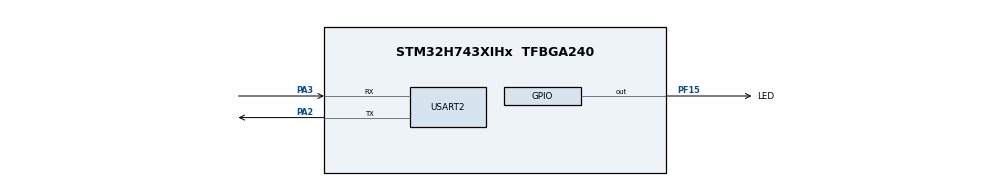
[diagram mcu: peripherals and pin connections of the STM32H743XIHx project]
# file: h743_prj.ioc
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CORTEX_M7.default_mode_Activation=1
FREERTOS.Queues01=uartQueue,128,1,1,Dynamic,NULL,NULL
FREERTOS.Tasks01=defaultTask,0,128,StartDefaultTask,Default,NULL,Dynamic,NULL,NULL
FREERTOS.configUSE_NEWLIB_REENTRANT=0
FREERTOS.configUSE_TICKLESS_IDLE=1
FREERTOS.configUSE_TIMERS=1
IWDG1.Prescaler=IWDG_PRESCALER_32
Mcu.Family=STM32H7
Mcu.Name=STM32H743XIHx
Mcu.Package=TFBGA240
NVIC.LPTIM1_IRQn=true\:5\:0\:false\:false\:true\:true\:true\:true\:true
NVIC.PriorityGroup=NVIC_PRIORITYGROUP_4
NVIC.TIM6_DAC_IRQn=true\:5\:0\:false\:false\:true\:true\:true\:true\:true
NVIC.TIM7_IRQn=true\:15\:0\:false\:false\:true\:false\:false\:true\:true
NVIC.TimeBase=TIM7_IRQn
NVIC.TimeBaseIP=TIM7
NVIC.USART2_IRQn=true\:5\:0\:false\:false\:true\:true\:true\:true\:true
PA13\ (JTMS/SWDIO).Mode=Serial_Wire
PA13\ (JTMS/SWDIO).Signal=DEBUG_JTMS-SWDIO
PA14\ (JTCK/SWCLK).Mode=Serial_Wire
PA14\ (JTCK/SWCLK).Signal=DEBUG_JTCK-SWCLK
PA2.Mode=Asynchronous
PA2.Signal=USART2_TX
PA3.Mode=Asynchronous
PA3.Signal=USART2_RX
PF15.GPIO_Label=LED
PF15.Signal=GPIO_Output
PH0-OSC_IN\ (PH0).Mode=HSE-External-Oscillator
PH0-OSC_IN\ (PH0).Signal=RCC_OSC_IN
PH1-OSC_OUT\ (PH1).Mode=HSE-External-Oscillator
PH1-OSC_OUT\ (PH1).Signal=RCC_OSC_OUT
ProjectManager.HeapSize=0x200
ProjectManager.StackSize=0x400
ProjectManager.TargetToolchain=MDK-ARM V5.32
RCC.ADCFreq_Value=50390625
RCC.APB1Freq_Value=120000000
RCC.APB2Freq_Value=120000000
RCC.APB3Freq_Value=120000000
RCC.APB4Freq_Value=120000000
RCC.CortexFreq_Value=480000000
RCC.D1PPRE=RCC_APB3_DIV2
RCC.D2PPRE1=RCC_APB1_DIV2
RCC.D2PPRE2=RCC_APB2_DIV2
RCC.D3PPRE=RCC_APB4_DIV2
RCC.DIVM1=5
RCC.DIVN1=192
RCC.HCLKFreq_Value=240000000
RCC.HPRE=RCC_HCLK_DIV2
RCC.LPTIM1CLockSelection=RCC_LPTIM1CLKSOURCE_LSI
RCC.PLLSourceVirtual=RCC_PLLSOURCE_HSE
RCC.SYSCLKFreq_VALUE=480000000
RCC.SYSCLKSource=RCC_SYSCLKSOURCE_PLLCLK
RCC.USBFreq_Value=480000000
TIM6.Period=99
TIM6.Prescaler=239
USART2.VirtualMode-Asynchronous=VM_ASYNC
VP_FREERTOS_VS_CMSIS_V1.Mode=CMSIS_V1
VP_IWDG1_VS_IWDG.Mode=IWDG_Activate
VP_LPTIM1_VS_LPTIM_counterModeInternalClock.Mode=Counts__internal_clock_event_00
VP_MEMORYMAP_VS_MEMORYMAP.Mode=CurAppReg
VP_SYS_VS_tim7.Mode=TIM7
VP_TIM6_VS_ClockSourceINT.Mode=Enable_Timer
board=custom

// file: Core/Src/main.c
/* USER CODE BEGIN Header */
/**
  ******************************************************************************
  * @file           : main.c
  * @brief          : Main program body
  ******************************************************************************
  * @attention
  *
  * Copyright (c) 2026 STMicroelectronics.
  * All rights reserved.
  *
  * This software is licensed under terms that can be found in the LICENSE file
  * in the root directory of this software component.
  * If no LICENSE file comes with this software, it is provided AS-IS.
  *
  ******************************************************************************
  */
/* USER CODE END Header */
#include "main.h"
#include "cmsis_os.h"
#include "iwdg.h"
#include "lptim.h"
#include "tim.h"
#include "usart.h"
#include "gpio.h"

/* USER CODE BEGIN Includes */
#include "FreeRTOS.h"
#include "task.h"
#include "queue.h"
#include "string.h"
#include "stdio.h"
#include "timers.h"
#include "test_api.h"
#include "cm_backtrace.h"
#include "event_groups.h"
/* USER CODE END Includes */

/* USER CODE BEGIN PTD */
// 定义事件位
#define BIT_TASK_1_DONE      (1 << 0)    //
#define BIT_TASK_2_DONE      (1 << 1)    //
#define BIT_TASK_3_DONE      (1 << 2)    //

#define BIT_TASK_ALL_DONE    (BIT_TASK_1_DONE | BIT_TASK_2_DONE | BIT_TASK_3_DONE)
/* USER CODE END PTD */

/* USER CODE BEGIN PD */
// 事件标志组句柄
EventGroupHandle_t xSensorEventGroup;
// 串口接收缓存
uint8_t rx_byte;
/* USER CODE END PD */

void SystemClock_Config(void);
static void MPU_Config(void);
void MX_FREERTOS_Init(void);
/* USER CODE BEGIN PFP */
void Task_1(void *pvParameters);
void Task_2(void *pvParameters);
void Task_3(void *pvParameters);
void Task_Monitor(void *pvParameters);

/* USER CODE END PFP */

int main(void)
{

  /* MPU Configuration--------------------------------------------------------*/
  MPU_Config();

  /* MCU Configuration--------------------------------------------------------*/

  /* Reset of all peripherals, Initializes the Flash interface and the Systick. */
  HAL_Init();

  /* Configure the system clock */
  SystemClock_Config();

  /* USER CODE BEGIN SysInit */
  HAL_EnableDBGStopMode();
  /* USER CODE END SysInit */

  /* Initialize all configured peripherals */
  MX_GPIO_Init();
  MX_TIM6_Init();
  MX_USART2_UART_Init();
  MX_LPTIM1_Init();
  MX_IWDG1_Init();
  /* USER CODE BEGIN 2 */
  // 初始化cmbacktrace
  cm_backtrace_init("h743_prj", "v1.0", "v1011");
  printf("System init done\r\n");

  HAL_IWDG_Refresh(&hiwdg1);

  xSensorEventGroup = xEventGroupCreate();
  if (xSensorEventGroup != NULL)
  {
    xTaskCreate(Task_1, "Task_1", 256, NULL, 1, NULL);
    xTaskCreate(Task_2, "Task_2", 256, NULL, 1, NULL);
    xTaskCreate(Task_3, "Task_3", 256, NULL, 1, NULL);
    xTaskCreate(Task_Monitor, "Monitor", 512, NULL, 2, NULL);

    // 启动tim6中断
    // HAL_TIM_Base_Start_IT(&htim6);
    // 启动串口接收
    // HAL_UART_Receive_IT(&huart2, &rx_byte, 1);

  }

  /* USER CODE END 2 */

  /* Call init function for freertos objects (in cmsis_os2.c) */
  MX_FREERTOS_Init();

  /* Start scheduler */
  osKernelStart();

  /* We should never get here as control is now taken by the scheduler */

  /* Infinite loop */
  /* USER CODE BEGIN WHILE */
  // uint8_t msg[] = "hello word\r\n";
  while (1)
  {
    /* USER CODE END WHILE */

  }
}

void SystemClock_Config(void)
{
  RCC_OscInitTypeDef RCC_OscInitStruct = {0};
  RCC_ClkInitTypeDef RCC_ClkInitStruct = {0};

  /** Supply configuration update enable
  */
  HAL_PWREx_ConfigSupply(PWR_LDO_SUPPLY);

  /** Configure the main internal regulator output voltage
  */
  __HAL_PWR_VOLTAGESCALING_CONFIG(PWR_REGULATOR_VOLTAGE_SCALE0);

  while(!__HAL_PWR_GET_FLAG(PWR_FLAG_VOSRDY)) {}

  /** Initializes the RCC Oscillators according to the specified parameters
  * in the RCC_OscInitTypeDef structure.
  */
  RCC_OscInitStruct.OscillatorType = RCC_OSCILLATORTYPE_LSI|RCC_OSCILLATORTYPE_HSE;
  RCC_OscInitStruct.HSEState = RCC_HSE_ON;
  RCC_OscInitStruct.LSIState = RCC_LSI_ON;
  RCC_OscInitStruct.PLL.PLLState = RCC_PLL_ON;
  RCC_OscInitStruct.PLL.PLLSource = RCC_PLLSOURCE_HSE;
  RCC_OscInitStruct.PLL.PLLM = 5;
  RCC_OscInitStruct.PLL.PLLN = 192;
  RCC_OscInitStruct.PLL.PLLP = 2;
  RCC_OscInitStruct.PLL.PLLQ = 2;
  RCC_OscInitStruct.PLL.PLLR = 2;
  RCC_OscInitStruct.PLL.PLLRGE = RCC_PLL1VCIRANGE_2;
  RCC_OscInitStruct.PLL.PLLVCOSEL = RCC_PLL1VCOWIDE;
  RCC_OscInitStruct.PLL.PLLFRACN = 0;
  if (HAL_RCC_OscConfig(&RCC_OscInitStruct) != HAL_OK)
  {
    Error_Handler();
  }

  /** Initializes the CPU, AHB and APB buses clocks
  */
  RCC_ClkInitStruct.ClockType = RCC_CLOCKTYPE_HCLK|RCC_CLOCKTYPE_SYSCLK
                              |RCC_CLOCKTYPE_PCLK1|RCC_CLOCKTYPE_PCLK2
                              |RCC_CLOCKTYPE_D3PCLK1|RCC_CLOCKTYPE_D1PCLK1;
  RCC_ClkInitStruct.SYSCLKSource = RCC_SYSCLKSOURCE_PLLCLK;
  RCC_ClkInitStruct.SYSCLKDivider = RCC_SYSCLK_DIV1;
  RCC_ClkInitStruct.AHBCLKDivider = RCC_HCLK_DIV2;
  RCC_ClkInitStruct.APB3CLKDivider = RCC_APB3_DIV2;
  RCC_ClkInitStruct.APB1CLKDivider = RCC_APB1_DIV2;
  RCC_ClkInitStruct.APB2CLKDivider = RCC_APB2_DIV2;
  RCC_ClkInitStruct.APB4CLKDivider = RCC_APB4_DIV2;

  if (HAL_RCC_ClockConfig(&RCC_ClkInitStruct, FLASH_LATENCY_4) != HAL_OK)
  {
    Error_Handler();
  }
}

/* USER CODE BEGIN 4 */

/* printf重定向 */
#ifdef GNU
int __io_putchar(int ch)
{
  HAL_UART_Transmit(&huart2, (uint8_t*)&ch, 1, 100);
  return ch;
}
#else
int fputc(int ch, FILE *f)
{
  while ((USART2->ISR & USART_ISR_TXE_TXFNF) == 0);
  USART2->TDR = (uint8_t)ch;
  return ch;
}
#endif

// 串口中断回调函数
void HAL_UART_RxCpltCallback(UART_HandleTypeDef *huart)
{
  if (huart->Instance == USART2)
  {

  }
}

/*  */
void Task_1(void *pvParameters)
{

  for (;;)
  {
    vTaskDelay(1000);
    xEventGroupSetBits(xSensorEventGroup, BIT_TASK_1_DONE);
  }
}

/*  */
void Task_2(void *pvParameters)
{
  for(;;)
  {
    vTaskDelay(1500);
    xEventGroupSetBits(xSensorEventGroup, BIT_TASK_2_DONE);
  }
}

/* 制造卡死任务 */
void Task_3(void *pvParameters)
{

  for (;;)
  {
    if ((USART2->ISR & USART_ISR_RXNE_RXFNE) != 0)
    {
      char cmd = USART2->RDR;
      if (cmd == 'K')
      {
        printf("[ERROR] Task 3 Crashed\r\n");
        while (1);
      }
    }

    vTaskDelay(pdMS_TO_TICKS(500));
    xEventGroupSetBits(xSensorEventGroup, BIT_TASK_3_DONE);
  }
}

/* 监控任务 */
void Task_Monitor(void *pvParameters)
{
  EventBits_t uBits = 0;

  for (;;)
  {
    uBits = xEventGroupWaitBits(
      xSensorEventGroup,
      BIT_TASK_ALL_DONE,
      pdTRUE,
      pdTRUE,
      pdMS_TO_TICKS(3000));

    if ((uBits & BIT_TASK_ALL_DONE) == BIT_TASK_ALL_DONE)
    {
      HAL_IWDG_Refresh(&hiwdg1);
      printf("wdg ok\r\n");
    }
    else
    {
      printf("wdg overtime\r\n");
    }
  }
}

/* USER CODE END 4 */

 /* MPU Configuration */

void MPU_Config(void)
{
  MPU_Region_InitTypeDef MPU_InitStruct = {0};

  /* Disables the MPU */
  HAL_MPU_Disable();

  /** Initializes and configures the Region and the memory to be protected
  */
  MPU_InitStruct.Enable = MPU_REGION_ENABLE;
  MPU_InitStruct.Number = MPU_REGION_NUMBER0;
  MPU_InitStruct.BaseAddress = 0x0;
  MPU_InitStruct.Size = MPU_REGION_SIZE_4GB;
  MPU_InitStruct.SubRegionDisable = 0x87;
  MPU_InitStruct.TypeExtField = MPU_TEX_LEVEL0;
  MPU_InitStruct.AccessPermission = MPU_REGION_NO_ACCESS;
  MPU_InitStruct.DisableExec = MPU_INSTRUCTION_ACCESS_DISABLE;
  MPU_InitStruct.IsShareable = MPU_ACCESS_SHAREABLE;
  MPU_InitStruct.IsCacheable = MPU_ACCESS_NOT_CACHEABLE;
  MPU_InitStruct.IsBufferable = MPU_ACCESS_NOT_BUFFERABLE;

  HAL_MPU_ConfigRegion(&MPU_InitStruct);
  /* Enables the MPU */
  HAL_MPU_Enable(MPU_PRIVILEGED_DEFAULT);

}

void HAL_TIM_PeriodElapsedCallback(TIM_HandleTypeDef *htim)
{
  /* USER CODE BEGIN Callback 0 */
  if (htim->Instance == TIM6)
  {

  }
  /* USER CODE END Callback 0 */
  if (htim->Instance == TIM7)
  {
    HAL_IncTick();
  }
}

void Error_Handler(void)
{
  __disable_irq();
  while (1)
  {
  }
}

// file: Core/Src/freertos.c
/* USER CODE BEGIN Header */
/**
  ******************************************************************************
  * File Name          : freertos.c
  * Description        : Code for freertos applications
  ******************************************************************************
  * @attention
  *
  * Copyright (c) 2026 STMicroelectronics.
  * All rights reserved.
  *
  * This software is licensed under terms that can be found in the LICENSE file
  * in the root directory of this software component.
  * If no LICENSE file comes with this software, it is provided AS-IS.
  *
  ******************************************************************************
  */
/* USER CODE END Header */

#include "FreeRTOS.h"
#include "task.h"
#include "main.h"
#include "cmsis_os.h"

osThreadId defaultTaskHandle;
osMessageQId uartQueueHandle;

void StartDefaultTask(void const * argument);

void MX_FREERTOS_Init(void); /* (MISRA C 2004 rule 8.1) */

/* GetIdleTaskMemory prototype (linked to static allocation support) */
void vApplicationGetIdleTaskMemory( StaticTask_t **ppxIdleTaskTCBBuffer, StackType_t **ppxIdleTaskStackBuffer, uint32_t *pulIdleTaskStackSize );

/* GetTimerTaskMemory prototype (linked to static allocation support) */
void vApplicationGetTimerTaskMemory( StaticTask_t **ppxTimerTaskTCBBuffer, StackType_t **ppxTimerTaskStackBuffer, uint32_t *pulTimerTaskStackSize );

/* USER CODE BEGIN PREPOSTSLEEP */
__weak void PreSleepProcessing(uint32_t ulExpectedIdleTime)
{
/* place for user code */
}

__weak void PostSleepProcessing(uint32_t ulExpectedIdleTime)
{
/* place for user code */
}
/* USER CODE END PREPOSTSLEEP */

/* USER CODE BEGIN GET_IDLE_TASK_MEMORY */
static StaticTask_t xIdleTaskTCBBuffer;
static StackType_t xIdleStack[configMINIMAL_STACK_SIZE];

void vApplicationGetIdleTaskMemory( StaticTask_t **ppxIdleTaskTCBBuffer, StackType_t **ppxIdleTaskStackBuffer, uint32_t *pulIdleTaskStackSize )
{
  *ppxIdleTaskTCBBuffer = &xIdleTaskTCBBuffer;
  *ppxIdleTaskStackBuffer = &xIdleStack[0];
  *pulIdleTaskStackSize = configMINIMAL_STACK_SIZE;
  /* place for user code */
}
/* USER CODE END GET_IDLE_TASK_MEMORY */

/* USER CODE BEGIN GET_TIMER_TASK_MEMORY */
static StaticTask_t xTimerTaskTCBBuffer;
static StackType_t xTimerStack[configTIMER_TASK_STACK_DEPTH];

void vApplicationGetTimerTaskMemory( StaticTask_t **ppxTimerTaskTCBBuffer, StackType_t **ppxTimerTaskStackBuffer, uint32_t *pulTimerTaskStackSize )
{
  *ppxTimerTaskTCBBuffer = &xTimerTaskTCBBuffer;
  *ppxTimerTaskStackBuffer = &xTimerStack[0];
  *pulTimerTaskStackSize = configTIMER_TASK_STACK_DEPTH;
  /* place for user code */
}
/* USER CODE END GET_TIMER_TASK_MEMORY */

void MX_FREERTOS_Init(void) {

  /* USER CODE BEGIN RTOS_TIMERS */
  /* start timers, add new ones, ... */
  #if 0
  /* USER CODE END RTOS_TIMERS */

  /* Create the queue(s) */
  /* definition and creation of uartQueue */
  osMessageQDef(uartQueue, 128, 1);
  uartQueueHandle = osMessageCreate(osMessageQ(uartQueue), NULL);

  /* USER CODE BEGIN RTOS_QUEUES */
  #endif
  #if 0
  /* add queues, ... */
  /* USER CODE END RTOS_QUEUES */

  /* Create the thread(s) */
  /* definition and creation of defaultTask */
  osThreadDef(defaultTask, StartDefaultTask, osPriorityNormal, 0, 128);
  defaultTaskHandle = osThreadCreate(osThread(defaultTask), NULL);

  /* USER CODE BEGIN RTOS_THREADS */
  #endif
  /* add threads, ... */
  /* USER CODE END RTOS_THREADS */

}

void StartDefaultTask(void const * argument)
{
  for(;;)
  {
    osDelay(1);
  }
}
